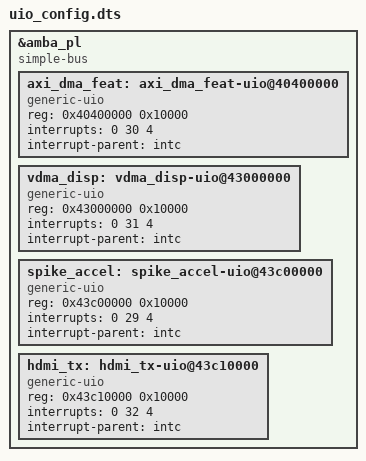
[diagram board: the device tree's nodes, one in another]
/*
 * Auto-generated by tools/ci/gen_dts.py from address_map.yaml.
 * DO NOT EDIT BY HAND. Regenerate after every Vivado BD change.
 * Contract 4 in docs/CONTRACTS.md.
 *
 * Owner: C2 (Driver & SDK).  This file is the *UIO overlay* — it exposes
 * each PL peripheral to user space via generic-uio so libspike_accel can
 * mmap /dev/uioN.  Vendor-driver bindings (axi-dma, axi-vdma, digilent-
 * axi-hdmi, xlnx,spike-accel) are owned by C1 and live in
 *   sw/petalinux/.../recipes-bsp/device-tree/files/spike-accel.dtsi
 * Node names here use the "<name>-uio@<addr>" suffix to avoid collision
 * with the C1 nodes (which keep the historical "<name>@<addr>" form).
 */

&amba_pl {
	compatible = "simple-bus"; #address-cells = <1>; #size-cells = <1>;

	axi_dma_feat: axi_dma_feat-uio@40400000 {
		compatible = "generic-uio";
		reg = <0x40400000 0x10000>;
		interrupts = <0 30 4>;
		interrupt-parent = <&intc>;
		status = "okay";
	};

	vdma_disp: vdma_disp-uio@43000000 {
		compatible = "generic-uio";
		reg = <0x43000000 0x10000>;
		interrupts = <0 31 4>;
		interrupt-parent = <&intc>;
		status = "okay";
	};

	spike_accel: spike_accel-uio@43c00000 {
		compatible = "generic-uio";
		reg = <0x43c00000 0x10000>;
		interrupts = <0 29 4>;
		interrupt-parent = <&intc>;
		clock-names = "pl_clk0";
		status = "okay";
	};

	hdmi_tx: hdmi_tx-uio@43c10000 {
		compatible = "generic-uio";
		reg = <0x43c10000 0x10000>;
		interrupts = <0 32 4>;
		interrupt-parent = <&intc>;
		status = "okay";
	};

};
